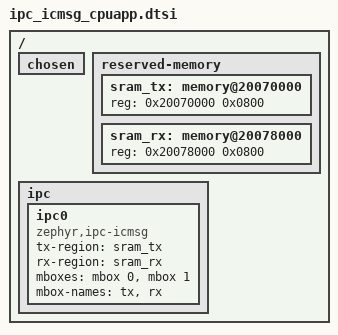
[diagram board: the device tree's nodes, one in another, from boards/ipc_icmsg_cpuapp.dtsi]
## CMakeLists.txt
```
cmake_minimum_required(VERSION 3.20.0)
find_package(Zephyr REQUIRED HINTS $ENV{ZEPHYR_BASE})
project(openpack_fw)
target_sources(app PRIVATE src/main.c)
target_include_directories(app PRIVATE include src/proto src/td src/app)
target_sources(app PRIVATE src/td/op_td.c) # AIR-3 / RX-4 time diversity (pack app core, receiver net core)
target_sources(app PRIVATE src/proto/proto.c src/proto/proto_rx.c src/proto/proto_pack.c)
if(CONFIG_OP_NRF5340 AND NOT CONFIG_SOC_COMPATIBLE_NRF5340_CPUNET)
  target_sources(app PRIVATE src/proto/proto_uart.c)
  target_sources_ifdef(CONFIG_OP_PERSIST app PRIVATE src/proto/op_store.c)
  target_sources_ifdef(CONFIG_OP_DFU app PRIVATE src/proto/op_dfu.c)
endif()
target_sources_ifdef(CONFIG_OP_NRF5340 app PRIVATE src/ipc.c)
if(CONFIG_OP_FEM_NRF21540 AND CONFIG_SOC_COMPATIBLE_NRF5340_CPUNET)
  target_sources(app PRIVATE src/net/op_fem.c)
endif()
if(CONFIG_OP_NRF5340 AND CONFIG_OP_ROLE_PACK)
  if(CONFIG_SOC_COMPATIBLE_NRF5340_CPUNET)
    target_sources(app PRIVATE src/net/sched.c)
  else()
    target_sources(app PRIVATE src/app/pack.c codec/adpcm6.c src/clk/op_clk.c src/clk/op_lead.c)
    target_sources_ifdef(CONFIG_OP_BATT app PRIVATE src/app/batt.c src/app/op_batt.c) # PK-8, ADR-0012 (#118)
    target_include_directories(app PRIVATE codec src/clk)
    if(CONFIG_ARCH_POSIX) # bsim: test-only frame clock offset (#97)
      target_sources(app PRIVATE src/app/bsim_fclk.c)
      target_include_directories(app PRIVATE $ENV{BSIM_COMPONENTS_PATH}/libUtilv1/src)
    endif()
    if(CONFIG_OP_TEST_APP_LOAD_PERIOD_US GREATER 0)
      target_sources(app PRIVATE src/app/testload.c)
    endif()
  endif()
endif()
if(CONFIG_OP_TEST_BSIM_ARGS)
  target_sources(app PRIVATE src/bsim_args.c)
  target_include_directories(app PRIVATE $ENV{BSIM_COMPONENTS_PATH}/libUtilv1/src)
endif()
include(src/rx/rx.cmake)
include(src/audio/audio.cmake)
```

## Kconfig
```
mainmenu "OpenPack firmware"

choice OP_ROLE
	prompt "Device role (FW-1)"
	default OP_ROLE_RX if BOARD_OPENPACK_RX
	default OP_ROLE_PACK

config OP_ROLE_PACK
	bool "Pack: transmitter worn by the performer"

config OP_ROLE_RX
	bool "Receiver module"

endchoice

# FW-5: every timing constant is Kconfig. Defaults from SPEC.md section 2 / AIR-4.
config OP_T_GAP_US
	int "Retune gap between copy A and copy B (us)"
	default 100

config OP_DAC_BLOCK_SAMPLES
	int "DAC DMA block (samples)"
	default 8

config OP_TIME_DIVERSITY
	bool "Time diversity on at boot (pack td setting, AIR-3 td_audio, RX-4, ADR-0017)"
	help
	  Packet n also carries frame n-2's codec_state + audio (td_audio, 39 B): 81 B payloads instead of
	  42 B, +2000 us latency (4.58 ms with PCM5102A FLT=1). Off by default (ADR-0017); a per-pack
	  configuration setting (td on|off, fw/PROTOCOL.md) for hostile venues, not switched mid-show.
	  The receiver needs no setting: it tells TD packs by payload length. Sysbuild: SB_CONFIG_OP_TIME_DIVERSITY.

config OP_RX_WINDOW_US
	int "Reserved RX window at the end of each frame (us)"
	default 0 if OP_TIME_DIVERSITY
	default 300
	help
	  AIR-4 / SYS-7 slot, idle in v1. Two 81 B TD copies end at t0 + 877 us, so a pack with TD on
	  forfeits it (ADR-0017): the TD build sets 0, and td on on a 300 us build sends into it.

config OP_PACK_ID
	int "Pack ID (AIR-2 access address), set from host/channel_plan.yaml"
	default 0
	range 0 7

config OP_CH_A_MHZ
	int "Copy A carrier (MHz, AIR-5)"
	default 2424
	range 2402 2440

config OP_CH_B_MHZ
	int "Copy B carrier (MHz, AIR-5: >= copy A + 40)"
	default 2473
	range 2442 2482
	help
	  2482 is UK/EU only (EN 300 328, ADR-0016); the pack's region setting caps fB at 2480 for us/jp
	  at runtime (fw/src/proto/proto_pack.c op_fb_max). BabbleSim's phy stops at 2480.

config OP_TEST_BSIM_ARGS
	bool "Test only: pack id and carriers from the bsim command line (-op_pack_id, -op_ch_a, -op_ch_b)"
	depends on ARCH_POSIX && SOC_COMPATIBLE_NRF5340_CPUNET
	default y
	help
	  bsim net core only (never on silicon): one build serves all 8 packs and receivers of the G2
	  scenarios (tests/bsim/scenarios, #27). Without the options the Kconfig values above apply.

config OP_PACK_FRAME_LEAD_US
	int "Pack: audio frame clock to net-core payload latch (us) = the frame thread's deadline (#87)"
	default 100
	range 1 499
	help
	  The app core places its 1 ms audio frame clock this far before the net core's latch
	  (OP_PACK_LATCH_LEAD_US before t0), from a sync the net core sends at start (ADR-0020). Read +
	  ADPCM-6 encode + IPC must finish inside it; then no frame is ever skipped. Every us here is
	  SYS-2 latency: SPEC section 2 "Encode + IPC" = this + OP_PACK_LATCH_LEAD_US. < 500: the net
	  core's margin report takes a frame within half a frame after its latch as late.

config OP_PACK_LATCH_LEAD_US
	int "Pack: net-core payload latch (TIMER0 COMPARE3) this far before TXEN of copy A (us, #98)"
	default 20
	range 5 100
	help
	  The newest frame is copied into the radio buffer this long before t0. It must follow the end
	  of copy B (t0 + 877 us at 81 B) and give the latch interrupt time before copy A's EasyDMA read
	  (t0 + ramp-up): 20 + 40 us. Every us here is SYS-2 latency (TD on with FLT=1: 4.6 ms budget).

config OP_PACK_LEAD_REPORT_FRAMES
	int "Pack: net core reports the latch margin to the app core every this many frames (#97)"
	default 100
	range 10 1000
	help
	  The app core's lead loop (ADR-0022) steers the audio frame clock rate from these reports. The
	  gains below assume 100 (one report = 100 ms).

config OP_PACK_LEAD_KP_PPB
	int "Pack lead loop proportional gain (ppb of frame clock rate per us of margin error)"
	default 2000

config OP_PACK_LEAD_KI_PPB
	int "Pack lead loop integral gain (ppb per us of margin error per report)"
	default 100

config OP_PACK_LEAD_LIM_PPB
	int "Pack lead loop correction limit (ppb), also the integrator clamp"
	default 100000

config OP_TEST_FCLK_PPB
	int "Test only: frame clock rate offset on the TIMER1 fallback (ppb); bsim -op_fclk_ppb overrides"
	default 0
	help
	  The bsim device has one crystal (-xo_drift moves TIMER0 and TIMER1 together), so the lead
	  loop is tested with this offset on the frame clock: +371 = HFCLKAUDIO at FREQ 39846, +-40000
	  for margin. Ignored by the I2S frame clock. Never set in a shipped build.

config OP_PACK_FRAME_PRIO
	int "Pack: frame thread priority (cooperative, above the system workqueue)"
	default -2

config OP_TEST_SCHED_REPORT
	bool "Test only: pack prints PACK_IPC (net) / PACK_FCLK (app) lines per second"
	depends on ARCH_POSIX
	default y if OP_TEST_BSIM_ARGS || SOC_COMPATIBLE_NRF5340_CPUAPP
	help
	  tests/bsim/sched/check.py reads the margin (latch - frame arrival); tests/bsim/scenarios/run.py
	  (a) the device time of t0 and of the audio frame clock. bsim only, never silicon.

config OP_TEST_APP_LOAD_PERIOD_US
	int "Test only: app-core load thread wakes every this many us, 0 = off (tests/bsim/sched, #87)"
	default 0
	help
	  Stress for FW-2: an unrelated app-core thread that wakes periodically and busy-works for
	  OP_TEST_APP_LOAD_BUSY_US. The pack must not skip a frame. Never set in a shipped build.

config OP_TEST_APP_LOAD_BUSY_US
	int "Test only: busy time per load-thread wake (us)"
	default 0

config OP_TEST_APP_LOAD_PRIO
	int "Test only: load thread priority"
	default 7

config OP_TEST_PROTO_POLL_MS
	int "Test only: console thread polls its RX semaphore every this many ms, 0 = wait forever (#87)"
	default 0
	help
	  Brings back the 50 ms console poll that exposed #87. The shipped build waits forever.

# #107 / ADR-0015: nRF21540 front-end on the BT40NE. Pack only: the receiver is a BT40E (ADR-0021).
config OP_FEM_NRF21540
	bool "nRF21540 FEM present (devicetree node nrf_radio_fem)"
	default y if DT_HAS_NORDIC_NRF21540_FEM_ENABLED

config OP_FEM_ANT_SEL_UFL
	int "ANT_SEL (P1.05) logical level that selects the u.FL port"
	default 1
	range 0 1
	depends on OP_FEM_NRF21540
	help
	  UNVERIFIED. The Fanstel BT40/BT40N/NE spec v1.09 (p.21-22) wires P1.05 to the nRF21540 ANT_SEL but does not
	  say which port is the u.FL. Nordic: ANT_SEL low = ANT1, high = ANT2. Default 1 assumes the u.FL is on ANT2.
	  Confirm with Fanstel or on the bench (conducted power at the u.FL, P1.05 low vs high) before Phase 5.

config OP_FEM_GAIN_DB
	int "nRF21540 PA gain with MODE high (POUTB), dB"
	default 10
	depends on OP_FEM_NRF21540
	help
	  nRF21540 MODE high selects POUTB, about 10 dB gain (low selects POUTA, about 20 dB). The firmware always
	  drives MODE to POUTB: +7 dBm conducted needs only the low-gain path (ADR-0015, ~38 mA at +10 dBm).

config OP_TX_SOC_DBM
	int "nRF5340 radio TXPOWER (dBm, 1 dB steps -4..3)"
	default -3 if OP_FEM_NRF21540
	default 0
	range -4 3
	help
	  Without a FEM (native_sim, BabbleSim) this is the conducted power. With the FEM the conducted power is
	  this plus OP_FEM_GAIN_DB.

config OP_TX_MAX_CONDUCTED_DBM
	int "Conducted TX power ceiling (dBm)"
	default 7
	help
	  Region UK, ADR-0015: 9 dBm EIRP declared = +7 dBm conducted into the 2 dBi whip, 1 dB under the 10 dBm
	  EN 300 328 non-adaptive line. A build whose OP_TX_SOC_DBM (+ OP_FEM_GAIN_DB with a FEM) exceeds this does
	  not compile (fw/src/net/op_fem.h). Raise it only for a US-region build (ADR-0015, FCC 15.247).

# PK-8 / ADR-0012 (#118): cell monitor on boards with the VBAT_SENSE divider (openpack_pack).
config OP_BATT
	bool "Pack battery LEDs and 3.3 V cutoff from the board's vbat voltage divider"
	default y if OP_ROLE_PACK && SOC_COMPATIBLE_NRF5340_CPUAPP && $(dt_nodelabel_enabled,vbat)
	select ADC
	select POWEROFF

config OP_BATT_CUTOFF_MV
	int "Shut down below this cell voltage, under load (mV, ADR-0012)"
	default 3300
	depends on OP_BATT

config OP_BATT_LOW_MV
	int "Battery LED red below this cell voltage (mV, PK-8)"
	default 3400
	depends on OP_BATT

config OP_BATT_HYST_MV
	int "Battery LED back to green this far above OP_BATT_LOW_MV (mV)"
	default 50
	depends on OP_BATT

config OP_BATT_CUTOFF_SAMPLES
	int "Consecutive samples below the cutoff before shutdown"
	default 5
	range 1 255
	depends on OP_BATT
	help
	  At one sample per second, 5 s below 3.3 V: a single TX current spike or ADC outlier does not end a show.

config OP_BATT_PERIOD_MS
	int "Battery sample period (ms)"
	default 1000
	depends on OP_BATT

# FW-2: the nRF5340 builds split work across cores over ipc0.
config OP_NRF5340
	bool
	default y if SOC_COMPATIBLE_NRF5340_CPUAPP || SOC_COMPATIBLE_NRF5340_CPUNET
	select IPC_SERVICE
	select MBOX

config OP_PERSIST
	bool "Pack: `save` writes the settings to flash (NVS) and boot reads them back (PK-9)"
	default y if OP_ROLE_PACK && OP_NRF5340 && !SOC_COMPATIBLE_NRF5340_CPUNET
	select FLASH
	select FLASH_MAP
	select NVS
	help
	  Two sectors at the start of storage_partition. Saved values override the OP_PACK_ID / OP_CH_* / OP_TIME_DIVERSITY
	  defaults at boot. The net core still takes its id and carriers from its own Kconfig until the app core
	  forwards them (#38).

config OP_DFU
	bool "`dfu` command: reboot into MCUboot serial recovery (PK-9, FW-6)"
	default y if BOOTLOADER_MCUBOOT && OP_NRF5340 && !SOC_COMPATIBLE_NRF5340_CPUNET
	select REBOOT
	select RETAINED_MEM
	select RETENTION
	select RETENTION_BOOT_MODE
	help
	  Needs the DT chosen zephyr,boot-mode (DK, openpack boards) and an MCUboot with BOOT_SERIAL_BOOT_MODE
	  (fw/sysbuild/mcuboot.conf). Updates the app core only: the net core image is not under MCUboot (fw/PROTOCOL.md).

config OP_CONSOLE_USB_CDC
	bool "Protocol on USB CDC ACM (PK-9) instead of the console UART"
	default y if $(dt_chosen_enabled,openpack-proto)
	select USB_DEVICE_STACK_NEXT
	select USBD_CDC_ACM_CLASS
	select UART_LINE_CTRL
	select CDC_ACM_SERIAL_INITIALIZE_AT_BOOT
	help
	  The chosen openpack-proto node (fw/boards/op_usb_cdc.dtsi) exists on the DK and the pack board only. The USB
	  stack is brought up at boot by Zephyr (CDC_ACM_SERIAL_INITIALIZE_AT_BOOT). uart0 keeps boot and log output.

if OP_CONSOLE_USB_CDC
config CDC_ACM_SERIAL_VID
	default 0x1209
config CDC_ACM_SERIAL_PID
	default 0x0001
config CDC_ACM_SERIAL_MANUFACTURER_STRING
	default "OpenPack"
config CDC_ACM_SERIAL_PRODUCT_STRING
	default "OpenPack console"
endif

rsource "src/rx/Kconfig"
rsource "src/rx_app/Kconfig"

choice OP_AUDIO_BACKEND
	prompt "Audio I/O backend (FW-3)"
	default OP_AUDIO_I2S if BOARD_NRF5340DK || BOARD_OPENPACK_PACK || BOARD_OPENPACK_RX
	default OP_AUDIO_WAV

config OP_AUDIO_WAV
	bool "WAV files on the host (native_sim, nrf5340bsim)"

config OP_AUDIO_I2S
	bool "I2S hardware: PCM1840 capture (pack), PCM5102A output (receiver)"

endchoice

config OP_AUDIO_WAV_IN
	string "Input WAV (48 kHz mono 16-bit); env OP_AUDIO_IN overrides"
	default "op_in.wav"
	depends on OP_AUDIO_WAV

config OP_AUDIO_WAV_OUT
	string "Output WAV; env OP_AUDIO_OUT overrides"
	default "op_out.wav"
	depends on OP_AUDIO_WAV

source "Kconfig.zephyr"
```

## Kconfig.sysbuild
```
# #120: MCUboot on the app core has no hardware RNG (the app core has none; the nRF5340 RNG is on the
# net core, reached over HCI, which MCUboot lacks). RSA via PSA then selects the insecure
# TEST_RANDOM_GENERATOR. ECDSA-P256 only verifies, so it needs no RNG: default it on our boards.
# Declared before the stock choice so this default wins.
choice BOOT_SIGNATURE_TYPE
	default BOOT_SIGNATURE_TYPE_ECDSA_P256 if $(BOARD) = "openpack_pack" || $(BOARD) = "openpack_rx"
endchoice

source "share/sysbuild/Kconfig"

config OP_ROLE_RX
	bool "Build the receiver role (default: pack); applied to app and net core images"
	default y if $(BOARD) = "openpack_rx"

config OP_TIME_DIVERSITY
	bool "Pack time diversity on at boot (ADR-0017); applied to app and net core images"

config NET_CORE_BOARD
	string
	default "nrf5340dk/nrf5340/cpunet" if $(BOARD) = "nrf5340dk"
	default "openpack_pack/nrf5340/cpunet" if $(BOARD) = "openpack_pack"
	default "openpack_rx/nrf5340/cpunet" if $(BOARD) = "openpack_rx"
	default "nrf5340bsim/nrf5340/cpunet" if $(BOARD_TARGET_STRING) = "NRF5340BSIM_NRF5340_CPUAPP"
```

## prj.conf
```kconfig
CONFIG_PRINTK=y
CONFIG_SERIAL=y
CONFIG_UART_INTERRUPT_DRIVEN=y
```

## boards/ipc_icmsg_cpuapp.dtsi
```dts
/* FW-2: ipc0 as icmsg (no OpenAMP), from zephyr samples/subsys/ipc/ipc_service/icmsg. */
/delete-node/ &sram0_shared;

/ {
	chosen {
		/delete-property/ zephyr,ipc_shm;
		/delete-property/ zephyr,bt-hci;
	};

	reserved-memory {
		#address-cells = <1>;
		#size-cells = <1>;

		sram_tx: memory@20070000 {
			reg = <0x20070000 0x0800>;
		};

		sram_rx: memory@20078000 {
			reg = <0x20078000 0x0800>;
		};
	};

	ipc {
		/delete-node/ ipc0;

		ipc0: ipc0 {
			compatible = "zephyr,ipc-icmsg";
			tx-region = <&sram_tx>;
			rx-region = <&sram_rx>;
			mboxes = <&mbox 0>, <&mbox 1>;
			mbox-names = "tx", "rx";
			status = "okay";
		};
	};
};
```

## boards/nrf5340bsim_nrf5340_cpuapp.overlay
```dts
#include "ipc_icmsg_cpuapp.dtsi"
```

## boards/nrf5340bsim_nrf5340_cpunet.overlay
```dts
#include "nrf5340dk_nrf5340_cpunet.overlay"

/* #107: bsim has no nRF21540 (and no GPIO devices for it): the FEM node is silicon-only. */
&nrf_radio_fem {
	status = "disabled";
};

&radio {
	/delete-property/ fem;
};
```

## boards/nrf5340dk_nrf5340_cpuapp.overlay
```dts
/* DK: icmsg IPC, and the protocol on the "nRF USB" connector (J3). uart0 (VCOM) keeps the log. */
#include "ipc_icmsg_cpuapp.dtsi"
#include "op_usb_cdc.dtsi"
```

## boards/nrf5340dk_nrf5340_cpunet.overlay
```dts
#include "ipc_icmsg_cpunet.dtsi"

/* #107: Fanstel BT40NE nRF21540 front-end (FEM), GPIO mode.
 * PLACEHOLDER on the nRF5340 DK. The pack board target (boards/openpack/openpack_pack, #118) generates the same node
 * from the netlist (gen_pins.py, which also checks the nRF21540 pads are NC on the board). The pins below are the
 * BT40NE module-internal wiring, so they are right on the pack and arbitrary on a DK.
 * PACK ONLY: the receiver sub-board is a BT40E with no nRF21540 (ADR-0021). Receiver builds (SB_CONFIG_OP_ROLE_RX)
 * disable this node through boards/role_rx_cpunet.overlay, and fw/src/rx/rx.c refuses to build with it enabled.
 *
 * Source: Fanstel, "BLE 5.3, 802.15.4 Modules, BT40/F/E/N/NE Product Specifications", Ver 1.09, July 2024
 * (https://fanstel.squarespace.com/s/BT40F_BT40N-Product-Specifications.pdf), pin table p.21 (BT40N/NE
 * internally wired nRF5340 pins) and "GPIO mode" devicetree sample p.22:
 *   TX_EN  = P0.21 (pad C2)    RX_EN = P0.27 (pad D2)    PDN = P0.26 (pad D1)
 *   MODE   = P1.04 (pad E0)    ANT_SEL = P1.05 (pad E1)  CSN = P1.06, MISO = P0.25 (SPI mode only, unused here)
 * The p.22 sample says mode = P0.24 (pad C3), which the p.21 table does not mark as an nRF21540 pin; the table (and
 * hw/pack/symbols.py _FEM) put MODE on pad E0 = P1.04, so the table wins. Confirm MODE with Fanstel before Phase 5:
 * on the pack, C3 = P0.24 is the I2S BCLK, so if the sample were right the two would collide.
 * Fanstel p.22 shows ant-sel-gpios as GPIO_ACTIVE_HIGH but does not say which level selects the u.FL.
 * Firmware therefore takes the level from CONFIG_OP_FEM_ANT_SEL_UFL (fw/Kconfig), a bench gate before Phase 5.
 */
/ {
	nrf_radio_fem: nrf21540_fem {
		compatible = "nordic,nrf21540-fem";
		tx-en-gpios = <&gpio0 21 GPIO_ACTIVE_HIGH>;
		rx-en-gpios = <&gpio0 27 GPIO_ACTIVE_HIGH>;
		pdn-gpios = <&gpio0 26 GPIO_ACTIVE_HIGH>;
		mode-gpios = <&gpio1 4 GPIO_ACTIVE_HIGH>;
		ant-sel-gpios = <&gpio1 5 GPIO_ACTIVE_HIGH>;
	};
};

&radio {
	fem = <&nrf_radio_fem>;
};
```

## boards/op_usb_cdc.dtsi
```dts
/* PK-9 / RX-9: the line protocol (fw/PROTOCOL.md) over USB CDC ACM. Needs a &zephyr_udc0 (the nRF USB device).
 * Not on bsim, which has no USB: there the protocol stays on uart0 (the pty).
 */
/ {
	chosen {
		openpack-proto = &cdc_acm_uart0;
	};
};

&zephyr_udc0 {
	cdc_acm_uart0: cdc_acm_uart0 {
		compatible = "zephyr,cdc-acm-uart";
	};
};
```

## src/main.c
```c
/* OpenPack: role (FW-1) x core (FW-2). Pack: app core sources frames, net core schedules them on air. */
#include <zephyr/kernel.h>
#include "op_frame.h"
#include "op_rx.h"
#include "op_batt.h"

#define ROLE (IS_ENABLED(CONFIG_OP_ROLE_PACK) ? "pack" : "rx")
#define NET  IS_ENABLED(CONFIG_SOC_COMPATIBLE_NRF5340_CPUNET)
#define CORE (NET ? "net" : IS_ENABLED(CONFIG_SOC_COMPATIBLE_NRF5340_CPUAPP) ? "app" : "host")

int main(void)
{
	printk("OpenPack role=%s core=%s t_gap_us=%d dac_block=%d rx_window_us=%d\n", ROLE, CORE,
	       CONFIG_OP_T_GAP_US, CONFIG_OP_DAC_BLOCK_SAMPLES, CONFIG_OP_RX_WINDOW_US);
#if defined(CONFIG_OP_NRF5340) && defined(CONFIG_OP_ROLE_PACK)
	int err;

	if (NET) {
		err = op_sched_start();
		if (err == 0) {
			err = op_ipc_init(op_sched_put);
		}
		if (err == 0) {
			err = op_sched_sync();
		}
	} else {
		err = op_pack_start();
		if (err == 0 && IS_ENABLED(CONFIG_OP_BATT)) {
			err = op_batt_start(); /* PK-8 LEDs, 3.3 V cutoff (ADR-0012) */
		}
	}
	printk("OpenPack %s pipeline %s (%d)\n", CORE, err ? "FAILED" : "up", err);
#elif defined(CONFIG_OP_NRF5340) && defined(CONFIG_OP_ROLE_RX)
	int err = NET ? op_ipc_init(NULL) : op_rx_app_start();

	err = (err == 0 && NET) ? op_rx_start() : err;
	printk("OpenPack %s rx pipeline %s (%d)\n", CORE, err ? "FAILED" : "up", err);
#endif
	return 0;
}
```

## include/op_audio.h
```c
/* OpenPack audio I/O (FW-3). One interface, backend chosen by Kconfig:
 * WAV file (native_sim, nrf5340bsim) or I2S (nrf5340dk, openpack_pack, openpack_rx; silicon bring-up in Phase 5).
 * Audio is 48 kHz mono signed 16-bit.
 */
#ifndef OP_AUDIO_H
#define OP_AUDIO_H

#include <stdint.h>

#define OP_AUDIO_RATE_HZ       48000
#define OP_AUDIO_FRAME_SAMPLES 48 /* 1 ms input frame */
#define OP_AUDIO_BLOCK_SAMPLES CONFIG_OP_DAC_BLOCK_SAMPLES

/* Open the backend. 0 on success, negative errno on failure
 * (-ENOTSUP: no audio on this core). */
int op_audio_start(void);

/* Read one frame of OP_AUDIO_FRAME_SAMPLES samples. 0 on success,
 * -ENODATA at end of input, other negative errno on failure. */
int op_audio_read_frame(int16_t *frame);

/* Write one DAC block of OP_AUDIO_BLOCK_SAMPLES samples. 0 or negative errno. */
int op_audio_write_block(const int16_t *block);

/* I2S backend, pack (#97): start capture; cb runs in the I2S interrupt once per completed frame
 * (RXPTRUPD), the audio frame clock. Steer its rate in whole HFCLKAUDIO steps (3311 ppb each). */
int op_audio_i2s_rx_start(void (*cb)(void));
void op_audio_i2s_aclk_steps(int32_t steps);
/* Pack: stop capture and put the PCM1840 back into shutdown (battery cutoff). */
void op_audio_i2s_stop(void);

/* I2S backend, receiver (#118): samples handed to the PCM5102A so far (zeros included). */
uint32_t op_audio_i2s_tx_out(void);

#endif /* OP_AUDIO_H */
```

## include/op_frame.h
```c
/* AIR-3 v1 frame (ADPCM-6): seq u8, status u16 LE, codec_state 3 B, audio 36 B. With time diversity on
 * (ADR-0017) the payload on air also carries frame n-2's td_audio: 81 B, see src/td/op_td.h.
 */
#pragma once
#include <stdbool.h>
#include <stdint.h>
#include <stddef.h>

#define OP_FRAME_LEN   42 /* v1 frame, and the TD-off payload */
#define OP_PAYLOAD_MAX 81 /* TD-on payload, OP_FRAME_TD_LEN */
#define OP_FRAME_US    1000

/* Pack id (AIR-2 address) and carrier pair (AIR-5): Kconfig, or the bsim command line on test builds
 * (CONFIG_OP_TEST_BSIM_ARGS, src/bsim_args.c), so one build serves every pack id in bsim.
 */
#if defined(CONFIG_OP_TEST_BSIM_ARGS)
extern int op_pack_id, op_ch_a_mhz, op_ch_b_mhz;
#define OP_PACK_ID  op_pack_id
#define OP_CH_A_MHZ op_ch_a_mhz
#define OP_CH_B_MHZ op_ch_b_mhz
#else
#define OP_PACK_ID  CONFIG_OP_PACK_ID
#define OP_CH_A_MHZ CONFIG_OP_CH_A_MHZ
#define OP_CH_B_MHZ CONFIG_OP_CH_B_MHZ
#endif

/* FW-2: one frame per IPC message, app core -> net core. Pack only, net -> app, once at start: the
 * latch sync (OP_SYNC_LEN bytes, u16 LE us to the net core's next payload latch, #87). Then every
 * CONFIG_OP_PACK_LEAD_REPORT_FRAMES frames the lead report (OP_LEAD_LEN bytes: i16 LE latch margin
 * of the earliest frame in the window, i16 LE of the latest; latch - arrival, us; #97). The length
 * tells them apart.
 */
#define OP_SYNC_LEN 2
#define OP_LEAD_LEN 4
int op_ipc_init(void (*rx)(const uint8_t *frame, size_t len));
int op_ipc_send(const uint8_t *frame, size_t len);

/* Net core, pack role: AIR-4 schedule. */
int op_sched_start(void);
int op_sched_sync(void);
void op_sched_put(const uint8_t *payload, size_t len); /* 42 B, or 81 B with TD on */
uint32_t op_sched_underruns(void);
uint32_t op_sched_overruns(void);

/* App core, pack role: audio -> ADPCM-6 -> IPC, one frame per audio frame (src/app/pack.c). Sends a
 * 42 B or, with the pack's `td` setting on (op_pack_td, src/proto/proto_uart.c), an 81 B payload.
 */
int op_pack_start(void);
bool op_pack_td(void);
```

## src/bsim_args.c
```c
/* Test only (CONFIG_OP_TEST_BSIM_ARGS, bsim net core): pack id and carrier pair from the command line,
 * so tests/bsim/scenarios (#27) runs 8 packs and 8 receivers from one pack and one receiver build.
 * Defaults are the Kconfig values; op_frame.h maps OP_PACK_ID / OP_CH_A_MHZ / OP_CH_B_MHZ here.
 */
#include "bs_cmd_line.h"
#include "bs_dynargs.h"
#include "posix_native_task.h"
#include "op_frame.h"

int op_pack_id = CONFIG_OP_PACK_ID;
int op_ch_a_mhz = CONFIG_OP_CH_A_MHZ;
int op_ch_b_mhz = CONFIG_OP_CH_B_MHZ;

/* The bsim parser writes a default into every dest, given or not: parse into scratch, copy when found. */
static int arg_id, arg_a, arg_b;

static void found_id(char *argv, int offset)
{
	op_pack_id = arg_id;
}

static void found_a(char *argv, int offset)
{
	op_ch_a_mhz = arg_a;
}

static void found_b(char *argv, int offset)
{
	op_ch_b_mhz = arg_b;
}

static void op_bsim_register_args(void)
{
	static bs_args_struct_t args[] = {
		{.option = "op_pack_id", .name = "id", .type = 'i', .dest = &arg_id, .call_when_found = found_id,
		 .descript = "OpenPack pack id 0-7 (AIR-2 access address), default CONFIG_OP_PACK_ID"},
		{.option = "op_ch_a", .name = "MHz", .type = 'i', .dest = &arg_a, .call_when_found = found_a,
		 .descript = "OpenPack copy A carrier (AIR-5), default CONFIG_OP_CH_A_MHZ"},
		{.option = "op_ch_b", .name = "MHz", .type = 'i', .dest = &arg_b, .call_when_found = found_b,
		 .descript = "OpenPack copy B carrier (AIR-5), default CONFIG_OP_CH_B_MHZ"},
		ARG_TABLE_ENDMARKER,
	};

	bs_add_extra_dynargs(args);
}

NATIVE_TASK(op_bsim_register_args, PRE_BOOT_1, 10);
```

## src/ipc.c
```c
/* FW-2: app <-> net core link over ipc_service (icmsg on ipc0), one AIR-3 frame per message. */
#include <errno.h>
#include <zephyr/kernel.h>
#include <zephyr/ipc/ipc_service.h>
#include "op_frame.h"

static K_SEM_DEFINE(bound, 0, 1);
static void (*rx_cb)(const uint8_t *frame, size_t len);
static struct ipc_ept ept;

static void on_bound(void *priv)
{
	k_sem_give(&bound);
}

static void on_recv(const void *data, size_t len, void *priv)
{
	if (rx_cb != NULL) {
		rx_cb(data, len);
	}
}

static struct ipc_ept_cfg cfg = {
	.name = "op_frame",
	.cb = {.bound = on_bound, .received = on_recv},
};

int op_ipc_init(void (*rx)(const uint8_t *frame, size_t len))
{
	const struct device *dev = DEVICE_DT_GET(DT_NODELABEL(ipc0));
	int err;

	rx_cb = rx;
	err = ipc_service_open_instance(dev);
	if (err != 0 && err != -EALREADY) {
		return err;
	}
	err = ipc_service_register_endpoint(dev, &ept, &cfg);
	if (err != 0) {
		return err;
	}
	return k_sem_take(&bound, K_SECONDS(1));
}

int op_ipc_send(const uint8_t *frame, size_t len)
{
	int n = ipc_service_send(&ept, frame, len);

	return n < 0 ? n : 0;
}
```
